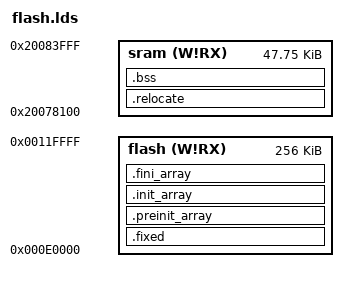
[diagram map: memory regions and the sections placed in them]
/* ----------------------------------------------------------------------------
 *         ATMEL Microcontroller Software Support
 * ----------------------------------------------------------------------------
 * Copyright (c) 2008, Atmel Corporation
 *
 * All rights reserved.
 *
 * Redistribution and use in source and binary forms, with or without
 * modification, are permitted provided that the following conditions are met:
 *
 * - Redistributions of source code must retain the above copyright notice,
 * this list of conditions and the disclaimer below.
 *
 * Atmel's name may not be used to endorse or promote products derived from
 * this software without specific prior written permission.
 *
 * DISCLAIMER: THIS SOFTWARE IS PROVIDED BY ATMEL "AS IS" AND ANY EXPRESS OR
 * IMPLIED WARRANTIES, INCLUDING, BUT NOT LIMITED TO, THE IMPLIED WARRANTIES OF
 * MERCHANTABILITY, FITNESS FOR A PARTICULAR PURPOSE AND NON-INFRINGEMENT ARE
 * DISCLAIMED. IN NO EVENT SHALL ATMEL BE LIABLE FOR ANY DIRECT, INDIRECT,
 * INCIDENTAL, SPECIAL, EXEMPLARY, OR CONSEQUENTIAL DAMAGES (INCLUDING, BUT NOT
 * LIMITED TO, PROCUREMENT OF SUBSTITUTE GOODS OR SERVICES; LOSS OF USE, DATA,
 * OR PROFITS; OR BUSINESS INTERRUPTION) HOWEVER CAUSED AND ON ANY THEORY OF
 * LIABILITY, WHETHER IN CONTRACT, STRICT LIABILITY, OR TORT (INCLUDING
 * NEGLIGENCE OR OTHERWISE) ARISING IN ANY WAY OUT OF THE USE OF THIS SOFTWARE,
 * EVEN IF ADVISED OF THE POSSIBILITY OF SUCH DAMAGE.
 * ----------------------------------------------------------------------------
 */

/*------------------------------------------------------------------------------
 *      Linker script for running in internal FLASH on the AT91SAM3U4
 *----------------------------------------------------------------------------*/

OUTPUT_FORMAT("elf32-littlearm", "elf32-littlearm", "elf32-littlearm")
OUTPUT_ARCH(arm)
ENTRY(ResetException)

/* Vector Definition */
/* vector is put at very begin adress of SRAM, the preserved size is 0x100 */
_vect_start = 0x20078000;

/* Memory Spaces Definitions */
MEMORY
{
    flash   (W!RX) : ORIGIN = 0x000E0000, LENGTH = 0x00040000   /* Flash, 256K  */
    sram    (W!RX) : ORIGIN = 0x20078100, LENGTH = 0x0000BF00   /* sramm ~48K   */
}

SECTIONS
{
    .fixed :
    {
        . = ALIGN(4);
        _sfixed = .;
        KEEP(*(.vectors))
        *(.text*)
        *(.rodata*)
        *(.glue_7)
        *(.glue_7t)
        . = ALIGN(4);
    } >flash

    .preinit_array : {
        PROVIDE_HIDDEN (__preinit_array_start = .);
        KEEP (*(.preinit_array*))
        PROVIDE_HIDDEN (__preinit_array_end = .);
    } >flash

    .init_array : {
        PROVIDE_HIDDEN (__init_array_start = .);
        KEEP (*(SORT(.init_array.*)))
        KEEP (*(.init_array*))
        PROVIDE_HIDDEN (__init_array_end = .);
    } >flash

    .fini_array : {
        PROVIDE_HIDDEN (__fini_array_start = .);
        KEEP (*(.fini_array*))
        KEEP (*(SORT(.fini_array.*)))
        PROVIDE_HIDDEN (__fini_array_end = .);
        _efixed = .;            /* End of text section */
    } >flash

    .relocate : AT (_efixed)
    {
        . = ALIGN(4);
        _srelocate = .;
        *(.ramfunc);
        *(.data);
		*(.data.*);
        . = ALIGN(4);
        _erelocate = .;
    } >sram

    .bss (NOLOAD) : {
        . = ALIGN(4);
        _szero = .;
	_bss = .;
        *(.bss)
	*(COMMON)
	_ebss = .;
        . = ALIGN(8);
        _ezero = .;
    } >sram

    /* Stack in the end of SRAM, double-word aligned */
    _estack = 0x20007FF8;
}
end = .;
PROVIDE(__HEAP_START = end );
